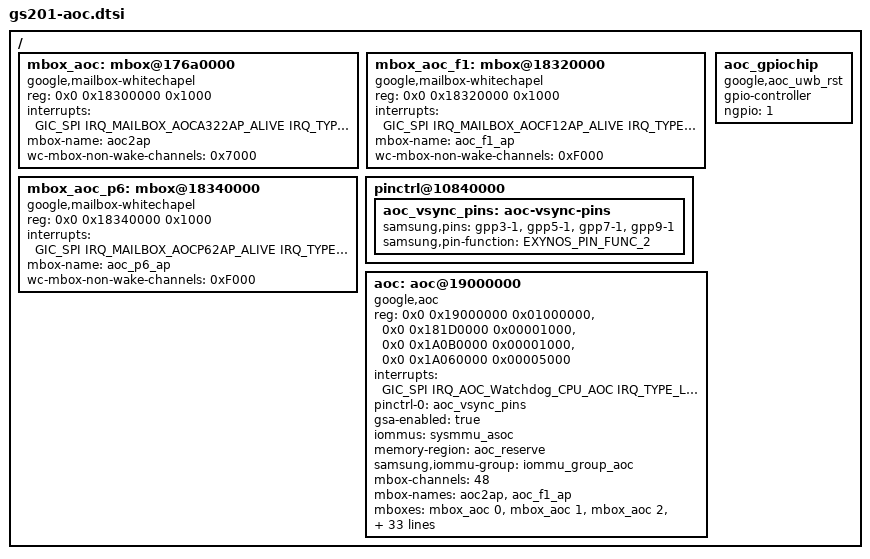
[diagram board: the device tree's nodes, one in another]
// SPDX-License-Identifier: GPL-2.0-only
/*
 * AoC device tree source
 *
 * Copyright 2019 Google,LLC.
 */

/ {
	mbox_aoc: mbox@176a0000 {
		compatible = "google,mailbox-whitechapel";
		#address-cells = <2>;
		#size-cells = <1>;
		reg = <0x0 0x18300000 0x1000>;
		interrupts = <GIC_SPI IRQ_MAILBOX_AOCA322AP_ALIVE
			IRQ_TYPE_LEVEL_HIGH>;
		mbox-name = "aoc2ap";
		#mbox-cells = <1>;

		wc-mbox-non-wake-channels = <0x7000>;
	};

	mbox_aoc_f1: mbox@18320000 {
		compatible = "google,mailbox-whitechapel";
		#address-cells = <2>;
		#size-cells = <1>;
		reg = <0x0 0x18320000 0x1000>;
		interrupts = <GIC_SPI IRQ_MAILBOX_AOCF12AP_ALIVE
				IRQ_TYPE_LEVEL_HIGH>;
		mbox-name = "aoc_f1_ap";
		#mbox-cells = <1>;

		wc-mbox-non-wake-channels = <0xF000>;
	};

	mbox_aoc_p6: mbox@18340000 {
		compatible = "google,mailbox-whitechapel";
		#address-cells = <2>;
		#size-cells = <1>;
		reg = <0x0 0x18340000 0x1000>;
		interrupts = <GIC_SPI IRQ_MAILBOX_AOCP62AP_ALIVE
				IRQ_TYPE_LEVEL_HIGH>;
		mbox-name = "aoc_p6_ap";
		#mbox-cells = <1>;

		wc-mbox-non-wake-channels = <0xF000>;
	};

	pinctrl@10840000 {
		aoc_vsync_pins: aoc-vsync-pins {
			/* go/p22-gpio */
			samsung,pins = "gpp3-1", "gpp5-1", "gpp7-1", "gpp9-1";
			samsung,pin-function = <EXYNOS_PIN_FUNC_2>;
		};
	};

	aoc: aoc@19000000 {
		compatible = "google,aoc";

		reg = <0x0 0x19000000 0x01000000>,
		      <0x0 0x181D0000 0x00001000>,
		      <0x0 0x1A0B0000 0x00001000>,
		      <0x0 0x1A060000 0x00005000>;

		reg-names = "blk_aoc", "aoc_req", "aoc_s2mpu", "ssmt_aoc";

		interrupts = <GIC_SPI IRQ_AOC_Watchdog_CPU_AOC
			IRQ_TYPE_LEVEL_HIGH>;
		interrupt-names = "watchdog";

		pinctrl-names = "default";
		pinctrl-0 = <&aoc_vsync_pins>;

		gsa-enabled = "true";

		iommus = <&sysmmu_asoc>;
		memory-region = <&aoc_reserve>;
		samsung,iommu-group = <&iommu_group_aoc>;

		mbox-channels = <48>;
		mbox-names = "aoc2ap", "aoc_f1_ap";
		mboxes = <&mbox_aoc 0
		&mbox_aoc 1
		&mbox_aoc 2
		&mbox_aoc 3
		&mbox_aoc 4
		&mbox_aoc 5
		&mbox_aoc 6
		&mbox_aoc 7
		&mbox_aoc 8
		&mbox_aoc 9
		&mbox_aoc 10
		&mbox_aoc 11
		&mbox_aoc 12
		&mbox_aoc 13
		&mbox_aoc 14
		&mbox_aoc 15
		&mbox_aoc_f1 0
		&mbox_aoc_f1 1
		&mbox_aoc_f1 2
		&mbox_aoc_f1 3
		&mbox_aoc_f1 4
		&mbox_aoc_f1 5
		&mbox_aoc_f1 6
		&mbox_aoc_f1 7
		&mbox_aoc_f1 8
		&mbox_aoc_f1 9
		&mbox_aoc_f1 10
		&mbox_aoc_f1 11
		&mbox_aoc_f1 12
		&mbox_aoc_f1 13
		&mbox_aoc_f1 14
		&mbox_aoc_f1 15
		&mbox_aoc_p6 0
		&mbox_aoc_p6 1
		&mbox_aoc_p6 2
		&mbox_aoc_p6 3
		&mbox_aoc_p6 4
		&mbox_aoc_p6 5
		&mbox_aoc_p6 6
		&mbox_aoc_p6 7
		&mbox_aoc_p6 8
		&mbox_aoc_p6 9
		&mbox_aoc_p6 10
		&mbox_aoc_p6 11
		&mbox_aoc_p6 12
		&mbox_aoc_p6 13
		&mbox_aoc_p6 14
		&mbox_aoc_p6 15
		>;

		acpm-ipc-channel = <13>;

		force-vnom = <0>;

		gsa-device = <&gsa>;

		pcu-base = <0xA00000>;
		gpio-base = <0xD70000>;
		pcu-db-set-offset = <0xD004>;
		pcu-db-clr-offset = <0xD008>;
		cp-aperture-start-offset = <0x7FDF80>;
		cp-aperture-end-offset = <0x7FFFFF>;
		clock-divider = <1>;

		channel-max-pending-msgs = <128>;
		block-channel-threshold = <64>;

		notify-on-state-transition = "true";
		hotword-supported = "true";
		chre-supported = "true";
	};
	aoc_gpiochip: aoc_gpiochip {
		compatible = "google,aoc_uwb_rst";
		gpio-controller;
		#gpio-cells = <2>;
		ngpio = <1>;
	};

};
